# WKUP_PSC0 register map
Vendor: Texas Instruments
Peripheral module from a debugger description file (folder J7VCL).
Registers are 32-bit, read-only, reset values left out (the file's numbers can be read two ways) unless marked. A register's access mark holds for its fields unless they carry their own. Offsets are as the file gives them; lines under a group give offsets from that group; [hi:lo] are bit positions; {n}, {i} and the like mark numbered series; 'fields as' and 'values as' point back to an identical list; <NAME> marks a mode.

## WKUP_PSC0
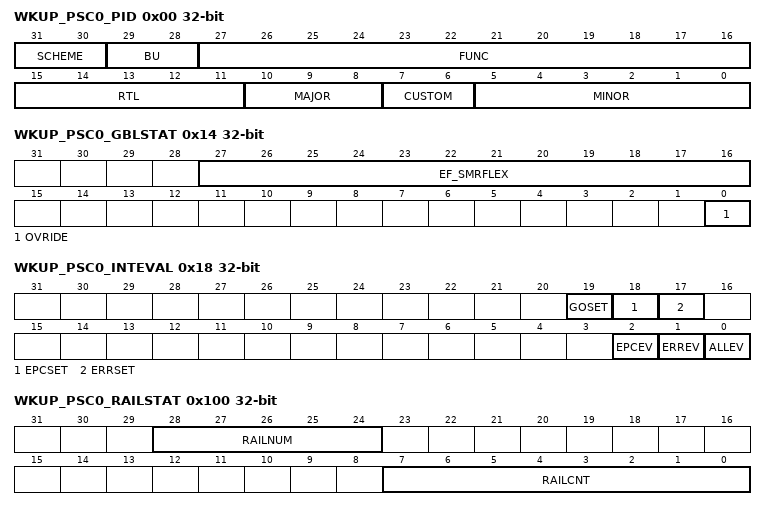
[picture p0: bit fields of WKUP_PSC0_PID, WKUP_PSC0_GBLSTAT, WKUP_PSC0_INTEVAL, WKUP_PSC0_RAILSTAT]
0x00 WKUP_PSC0_PID — The peripheral identification register is a constant register that contains the ID and ID revision number for that module. The WKUP_PSC0_PID stores version information used to identify the module. All bits within this register are read-only (writes have no effect) meaning that the values within this register should be hard-coded with the appropriate values and must not change from their hard-coded values.
  [31:30] SCHEME — WKUP_PSC0_PID register scheme
  [29:28] BU — Business Unit
  [27:16] FUNC — Module ID
  [15:11] RTL — RTL revision.
  [10:8] MAJOR — Major revision
  [7:6] CUSTOM
  [5:0] MINOR — Minor revision
0x10 WKUP_PSC0_GBLCTL — This register contains global control to PSC.
  [15:8] IO_ANA_CTL — General purpose IO/Analog PowerDown control.
0x14 WKUP_PSC0_GBLSTAT — This register shows the PSC global status.
  [27:16] EF_SMRFLEX — Smart reflex class0 bits
  [0] OVRIDE — PSC Override Status
0x18 WKUP_PSC0_INTEVAL wo — This register has no storage. Read from this register returns 0.
  [19] GOSET — GOSTAT Interrupt Set
  [18] EPCSET — External Power Control Interrupt Set
  [17] ERRSET — Combined Interrupt Set
  [2] EPCEV — External Power Control Interrupt Set
  [1] ERREV — Re_evaluate Error Interrupt
  [0] ALLEV — Re_evaluate combined PSC interrupt
0x40 WKUP_PSC0_MERRPR — This register records pending error conditions for all modules. Each bit represents one module (index 0 for modules 0-31, index 1 for modules 32-63, etc.).
  [31:0] M — Records pending error conditions.
0x50 WKUP_PSC0_MERRCR access not given — This register has no storage. Read from this register returns 0. Each bit represents one module (index 0 for modules 0-31, index 1 for modules 32-63, etc.).
  [31:0] M — Write of 1 clears the corresponding WKUP_PSC0_MERRPR bit. (access W1C)
0x60 WKUP_PSC0_PERRPR — This register records pending error conditions for each power domain. Each bit represents one domain (index 0 for domains 0-31, index 1 for domains 32-63, etc.).
  [31:0] P — Power Domain n Error Condition.
0x68 WKUP_PSC0_PERRCR access not given — This register has no storage. Read from this register returns 0. Each bit represents one domain (index 0 for domains 0-31, index 1 for domains 32-63, etc.).
  [31:0] P — Write of 1 clears the corresponding WKUP_PSC0_PERRPR bit. (access W1C)
0x70 WKUP_PSC0_EPCPR — This register records pending external power control conditions. Each bit represents one domain (index 0 for domains 0-31, index 1 for domains 32-63, etc.).
  [31:0] EPC — External Power Control Intervention Request for Power Domain n
0x78 WKUP_PSC0_EPCCR access not given — This register has no storage. Read from this register returns 0. Each bit represents one domain (index 0 for domains 0-31, index 1 for domains 32-63, etc.).
  [31:0] EPC — Write of 1 clears the corresponding WKUP_PSC0_EPCPR bit (access W1C)
0x100 WKUP_PSC0_RAILSTAT — This register is a read-only and shows the current rail requestor whose request is being granted and the current value of the counter associated with this requestor.
  [28:24] RAILNUM — Indicates Current Rail Requestor being processed by GPSC
  [7:0] RAILCNT — Indicates the current rail counter value
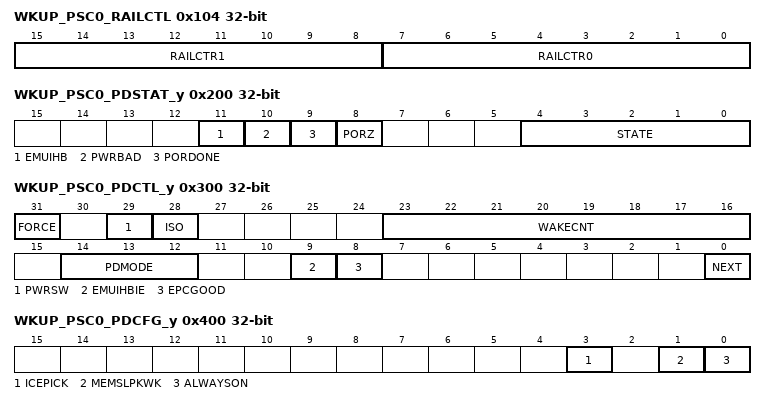
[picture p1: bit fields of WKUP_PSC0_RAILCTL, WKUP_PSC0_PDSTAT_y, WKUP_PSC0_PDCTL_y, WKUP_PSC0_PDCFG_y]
0x104 WKUP_PSC0_RAILCTL rw — This register is user programmable. It holds the counter values for rail counter. User can select one of the two counter values to be used for each power domain (see WKUP_PSC0_RAILSEL register).
  [15:8] RAILCTR1 — Rail Counter Value 1
  [7:0] RAILCTR0 — Rail Counter Value 0
0x108 WKUP_PSC0_RAILSEL rw — User can use this register to select the counter value (WKUP_PSC0_RAILCTL) for each power domain.
  [31:0] P — Rail Counter Select for Power Domain
0x120 WKUP_PSC0_PTCMD access not given — This is a pseudo-command register with no actual storage. Reads return 0. One bit for each power domain (index 0 for domains 0-31, index 1 for domains 32-63, etc.).
  [31:0] GO — Power Domain n GO Transition (access W1S)
0x128 WKUP_PSC0_PTSTAT — This is a status register. One bit for each power domain (index 0 for domains 0-31, index 1 for domains 32-63, etc.).
  [31:0] GOSTAT — Power Domain n Transition Command Status
0x200 WKUP_PSC0_PDSTAT_y — This is a status register. One register per power domain. Each register contains the status for the given power domain. Offset = 200h + (y * 4h); where y = 0h to 1h
  [11] EMUIHB — Emulation Alters Domain State
  [10] PWRBAD — Power Bad error
  [9] PORDONE — POR Done Input Status
  [8] PORZ — PORz output actual status
  [4:0] STATE — Current Power Domain State
0x300 WKUP_PSC0_PDCTL_y rw — This is a control register. One register per power domain. Offset = 300h + (y * 4h); where y = 0h to 1h
  [31] FORCE — Force Bit
  [29] PWRSW — Power shorting Switch Control
  [28] ISO — Isolation Cell control
  [23:16] WAKECNT — RAM wake count delay value
  [14:12] PDMODE — Power Down mode
  [9] EMUIHBIE — Emulation alters domain state
  [8] EPCGOOD — External Power Control Power Good Indication
  [0] NEXT — User_Desired Next Power Domain State Current Power Domain State
0x400 WKUP_PSC0_PDCFG_y — This is a status register. It shows PSC settings for easy debug. Offset = 400h + (y * 4h); where y = 0h to 1h
  [3] ICEPICK — Icepick support
  [1] MEMSLPKWK — Memory sleep-wake domain
  [0] ALWAYSON — Always on power domain Current Power Domain State
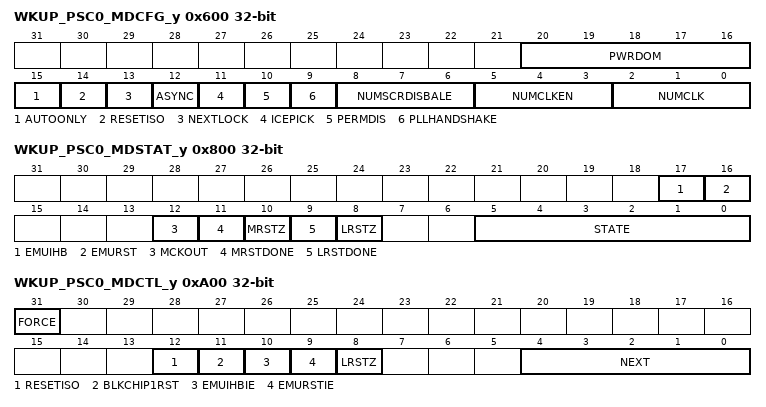
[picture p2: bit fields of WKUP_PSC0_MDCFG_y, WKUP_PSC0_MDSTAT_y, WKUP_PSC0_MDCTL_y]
0x600 WKUP_PSC0_MDCFG_y — This is a constant register showing some PSC settings for easy debug. This register is read only. Offset = 600h + (y * 4h); where y = 0h to 15h
  [20:16] PWRDOM — Indicates which power domain this module belongs to
  [15] AUTOONLY
  [14] RESETISO
  [13] NEXTLOCK
  [12] ASYNC — Async Lpsc
  [11] ICEPICK — IcePick support
  [10] PERMDIS — Permanently disable
  [9] PLLHANDSHAKE — RTL parameter PLL_HANDSHAKE
  [8:6] NUMSCRDISBALE — Number of PWR_SCR_DISABLE interfaces required on LPSC
  [5:3] NUMCLKEN — Number of PWR_CLK_EN interfaces required on LPSC
  [2:0] NUMCLK — Number of PWR_CLKSTOP interfaces required on LPSC
0x800 WKUP_PSC0_MDSTAT_y — This register shows the status of each module. Requires one register per module on the device. Offset = 800h + (y * 4h); where y = 0h to 15h
  [17] EMUIHB — Emulation Alters Module State.
  [16] EMURST — Emulation Alters Reset
  [12] MCKOUT — Actual modclk output to module Current Power Domain State
  [11] MRSTDONE — Module reset initialization done status
  [10] MRSTZ — Module reset actual status
  [9] LRSTDONE — Module local reset initialization done status
  [8] LRSTZ — Module local reset actual status
  [5:0] STATE — These bits indicate the current module state
0xA00 WKUP_PSC0_MDCTL_y rw — This register provides specific control for the individual module. One register per module on the device. Offset = A00h + (y * 4h); where y = 0h to 15h
  [31] FORCE — Force Bit
  [12] RESETISO — Reset Isolation
  [11] BLKCHIP1RST — Block Chip_1_Reset
  [10] EMUIHBIE — Emulation Alters Module State.
  [9] EMURSTIE — Emulation Alter Reset Interrupt Enable
  [8] LRSTZ — Module local reset control
  [4:0] NEXT — Module Next State
